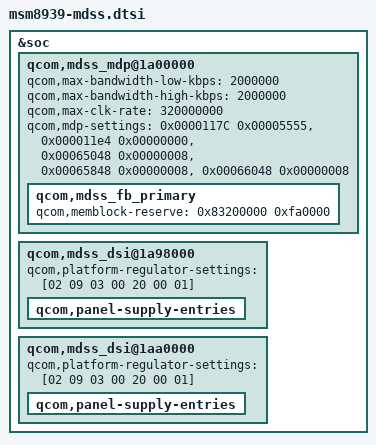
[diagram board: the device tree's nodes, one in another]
/* Copyright (c) 2014, The Linux Foundation. All rights reserved.
 *
 * This program is free software; you can redistribute it and/or modify
 * it under the terms of the GNU General Public License version 2 and
 * only version 2 as published by the Free Software Foundation.
 *
 * This program is distributed in the hope that it will be useful,
 * but WITHOUT ANY WARRANTY; without even the implied warranty of
 * MERCHANTABILITY or FITNESS FOR A PARTICULAR PURPOSE.  See the
 * GNU General Public License for more details.
 */

&soc {
	qcom,mdss_mdp@1a00000 {
		qcom,max-bandwidth-low-kbps = <2000000>;
		qcom,max-bandwidth-high-kbps = <2000000>;
		qcom,max-clk-rate = <320000000>;
		qcom,mdp-settings = <0x0000117C 0x00005555>,
				    <0x000011e4 0x00000000>,
				    <0x00065048 0x00000008>,
				    <0x00065848 0x00000008>,
				    <0x00066048 0x00000008>;

		qcom,mdss_fb_primary {
			qcom,memblock-reserve = <0x83200000 0xfa0000>;
		};
	};

	qcom,mdss_dsi@1a98000 {
		/delete-property/ vdd-supply;
		qcom,platform-regulator-settings = [02 09 03 00 20 00 01];

		qcom,panel-supply-entries {
			/delete-node/ qcom,panel-supply-entry@0;
		};
	};

	qcom,mdss_dsi@1aa0000 {
		/delete-property/ vdd-supply;
		qcom,platform-regulator-settings = [02 09 03 00 20 00 01];

		qcom,panel-supply-entries {
			/delete-node/ qcom,panel-supply-entry@0;
		};
	};
};
